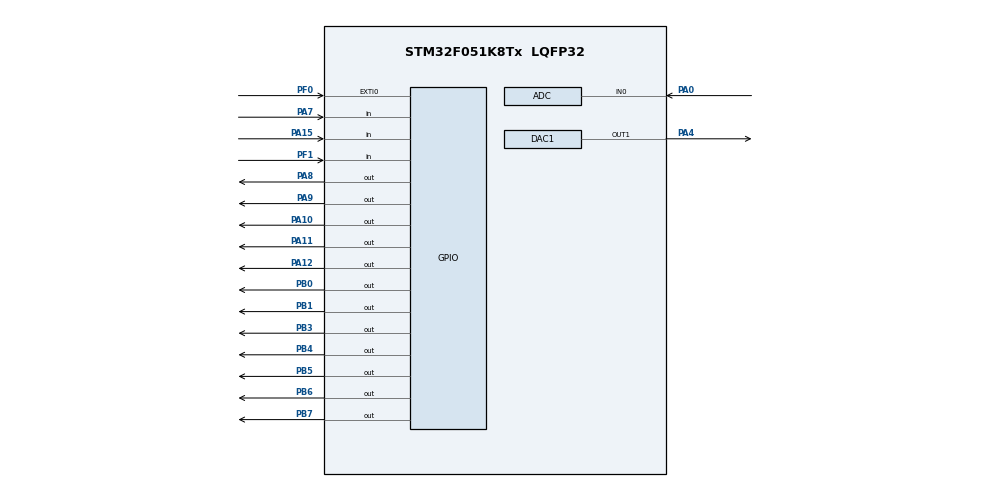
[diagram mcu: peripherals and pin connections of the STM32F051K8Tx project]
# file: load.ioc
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DAC1.DAC_OutputBuffer=DAC_OUTPUTBUFFER_DISABLE
Mcu.Family=STM32F0
Mcu.Name=STM32F051K8Tx
Mcu.Package=LQFP32
NVIC.EXTI0_1_IRQn=true\:0\:0\:false\:false\:true\:true\:true
PA0.Mode=IN0
PA0.Signal=ADC_IN0
PA10.GPIO_Speed=GPIO_SPEED_FREQ_HIGH
PA10.Signal=GPIO_Output
PA11.GPIO_Speed=GPIO_SPEED_FREQ_HIGH
PA11.PinState=GPIO_PIN_RESET
PA11.Signal=GPIO_Output
PA12.GPIO_Speed=GPIO_SPEED_FREQ_HIGH
PA12.PinState=GPIO_PIN_RESET
PA12.Signal=GPIO_Output
PA13.Mode=Serial_Wire
PA13.Signal=SYS_SWDIO
PA14.Mode=Serial_Wire
PA14.Signal=SYS_SWCLK
PA15.GPIO_PuPd=GPIO_PULLUP
PA15.Signal=GPIO_Input
PA4.Signal=COMP_DAC11_group
PA7.GPIO_PuPd=GPIO_PULLUP
PA7.Signal=GPIO_Input
PA8.GPIO_Speed=GPIO_SPEED_FREQ_HIGH
PA8.Signal=GPIO_Output
PA9.GPIO_Speed=GPIO_SPEED_FREQ_HIGH
PA9.Signal=GPIO_Output
PB0.PinState=GPIO_PIN_RESET
PB0.Signal=GPIO_Output
PB1.GPIO_Speed=GPIO_SPEED_FREQ_LOW
PB1.PinState=GPIO_PIN_RESET
PB1.Signal=GPIO_Output
PB3.GPIO_Speed=GPIO_SPEED_FREQ_HIGH
PB3.Signal=GPIO_Output
PB4.GPIO_Speed=GPIO_SPEED_FREQ_HIGH
PB4.Signal=GPIO_Output
PB5.GPIO_Speed=GPIO_SPEED_FREQ_HIGH
PB5.Signal=GPIO_Output
PB6.GPIO_Speed=GPIO_SPEED_FREQ_HIGH
PB6.Signal=GPIO_Output
PB7.GPIO_Speed=GPIO_SPEED_FREQ_HIGH
PB7.Signal=GPIO_Output
PF0-OSC_IN.GPIO_ModeDefaultEXTI=GPIO_MODE_IT_RISING
PF0-OSC_IN.Signal=GPXTI0
PF1-OSC_OUT.Signal=GPIO_Input
ProjectManager.HeapSize=0x000
ProjectManager.StackSize=0x400
ProjectManager.TargetToolchain=MDK-ARM V5
RCC.AHBCLKDivider=RCC_SYSCLK_DIV8
RCC.AHBFreq_Value=1000000
RCC.APB1Freq_Value=1000000
RCC.APB1TimFreq_Value=1000000
RCC.HCLKFreq_Value=1000000
SH.COMP_DAC11_group.0=DAC1_OUT1,DAC_OUT1
board=custom

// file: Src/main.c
/* USER CODE BEGIN Header */
/**
  ******************************************************************************
  * @file           : main.c
  * @brief          : Main program body
  ******************************************************************************
  * @attention
  *
  * <h2><center>&copy; Copyright (c) 2019 STMicroelectronics.
  * All rights reserved.</center></h2>
  *
  * This software component is licensed by ST under BSD 3-Clause license,
  * the "License"; You may not use this file except in compliance with the
  * License. You may obtain a copy of the License at:
  *                        opensource.org/licenses/BSD-3-Clause
  *
  ******************************************************************************
  */
/* USER CODE END Header */

#include "main.h"

/* USER CODE BEGIN Includes */
#include <board.h>

/* USER CODE END Includes */

ADC_HandleTypeDef hadc;

DAC_HandleTypeDef hdac1;

void SystemClock_Config(void);
static void MX_GPIO_Init(void);
static void MX_ADC_Init(void);
static void MX_DAC1_Init(void);

int main(void)
{

  /* MCU Configuration--------------------------------------------------------*/

  /* Reset of all peripherals, Initializes the Flash interface and the Systick. */
  HAL_Init();

  /* Configure the system clock */
  SystemClock_Config();

  /* Initialize all configured peripherals */
  MX_GPIO_Init();
  MX_ADC_Init();
  MX_DAC1_Init();
  /* USER CODE BEGIN 2 */

  user_init();

  /* USER CODE END 2 */

  /* Infinite loop */
  while (1)
  {

    /* USER CODE BEGIN 3 */

    user_loop();
  }
  /* USER CODE END 3 */
}

void SystemClock_Config(void)
{
  RCC_OscInitTypeDef RCC_OscInitStruct = {0};
  RCC_ClkInitTypeDef RCC_ClkInitStruct = {0};

  /** Initializes the CPU, AHB and APB busses clocks
  */
  RCC_OscInitStruct.OscillatorType = RCC_OSCILLATORTYPE_HSI|RCC_OSCILLATORTYPE_HSI14;
  RCC_OscInitStruct.HSIState = RCC_HSI_ON;
  RCC_OscInitStruct.HSI14State = RCC_HSI14_ON;
  RCC_OscInitStruct.HSICalibrationValue = RCC_HSICALIBRATION_DEFAULT;
  RCC_OscInitStruct.HSI14CalibrationValue = 16;
  RCC_OscInitStruct.PLL.PLLState = RCC_PLL_NONE;
  if (HAL_RCC_OscConfig(&RCC_OscInitStruct) != HAL_OK)
  {
    Error_Handler();
  }
  /** Initializes the CPU, AHB and APB busses clocks
  */
  RCC_ClkInitStruct.ClockType = RCC_CLOCKTYPE_HCLK|RCC_CLOCKTYPE_SYSCLK
                              |RCC_CLOCKTYPE_PCLK1;
  RCC_ClkInitStruct.SYSCLKSource = RCC_SYSCLKSOURCE_HSI;
  RCC_ClkInitStruct.AHBCLKDivider = RCC_SYSCLK_DIV8;
  RCC_ClkInitStruct.APB1CLKDivider = RCC_HCLK_DIV1;

  if (HAL_RCC_ClockConfig(&RCC_ClkInitStruct, FLASH_LATENCY_0) != HAL_OK)
  {
    Error_Handler();
  }
}

static void MX_ADC_Init(void)
{

  ADC_ChannelConfTypeDef sConfig = {0};

  /** Configure the global features of the ADC (Clock, Resolution, Data Alignment and number of conversion)
  */
  hadc.Instance = ADC1;
  hadc.Init.ClockPrescaler = ADC_CLOCK_ASYNC_DIV1;
  hadc.Init.Resolution = ADC_RESOLUTION_12B;
  hadc.Init.DataAlign = ADC_DATAALIGN_RIGHT;
  hadc.Init.ScanConvMode = ADC_SCAN_DIRECTION_FORWARD;
  hadc.Init.EOCSelection = ADC_EOC_SINGLE_CONV;
  hadc.Init.LowPowerAutoWait = DISABLE;
  hadc.Init.LowPowerAutoPowerOff = DISABLE;
  hadc.Init.ContinuousConvMode = DISABLE;
  hadc.Init.DiscontinuousConvMode = DISABLE;
  hadc.Init.ExternalTrigConv = ADC_SOFTWARE_START;
  hadc.Init.ExternalTrigConvEdge = ADC_EXTERNALTRIGCONVEDGE_NONE;
  hadc.Init.DMAContinuousRequests = DISABLE;
  hadc.Init.Overrun = ADC_OVR_DATA_PRESERVED;
  if (HAL_ADC_Init(&hadc) != HAL_OK)
  {
    Error_Handler();
  }
  /** Configure for the selected ADC regular channel to be converted.
  */
  sConfig.Channel = ADC_CHANNEL_0;
  sConfig.Rank = ADC_RANK_CHANNEL_NUMBER;
  sConfig.SamplingTime = ADC_SAMPLETIME_1CYCLE_5;
  if (HAL_ADC_ConfigChannel(&hadc, &sConfig) != HAL_OK)
  {
    Error_Handler();
  }

}

static void MX_DAC1_Init(void)
{

  DAC_ChannelConfTypeDef sConfig = {0};

  /** DAC Initialization
  */
  hdac1.Instance = DAC;
  if (HAL_DAC_Init(&hdac1) != HAL_OK)
  {
    Error_Handler();
  }
  /** DAC channel OUT1 config
  */
  sConfig.DAC_Trigger = DAC_TRIGGER_NONE;
  sConfig.DAC_OutputBuffer = DAC_OUTPUTBUFFER_DISABLE;
  if (HAL_DAC_ConfigChannel(&hdac1, &sConfig, DAC_CHANNEL_1) != HAL_OK)
  {
    Error_Handler();
  }

}

static void MX_GPIO_Init(void)
{
  GPIO_InitTypeDef GPIO_InitStruct = {0};

  /* GPIO Ports Clock Enable */
  __HAL_RCC_GPIOF_CLK_ENABLE();
  __HAL_RCC_GPIOA_CLK_ENABLE();
  __HAL_RCC_GPIOB_CLK_ENABLE();

  /*Configure GPIO pin Output Level */
  HAL_GPIO_WritePin(GPIOB, GPIO_PIN_0|GPIO_PIN_1|GPIO_PIN_3|GPIO_PIN_4
                          |GPIO_PIN_5|GPIO_PIN_6|GPIO_PIN_7, GPIO_PIN_RESET);

  /*Configure GPIO pin Output Level */
  HAL_GPIO_WritePin(GPIOA, GPIO_PIN_8|GPIO_PIN_9|GPIO_PIN_10|GPIO_PIN_11
                          |GPIO_PIN_12, GPIO_PIN_RESET);

  /*Configure GPIO pin : PF0 */
  GPIO_InitStruct.Pin = GPIO_PIN_0;
  GPIO_InitStruct.Mode = GPIO_MODE_IT_RISING;
  GPIO_InitStruct.Pull = GPIO_NOPULL;
  HAL_GPIO_Init(GPIOF, &GPIO_InitStruct);

  /*Configure GPIO pin : PF1 */
  GPIO_InitStruct.Pin = GPIO_PIN_1;
  GPIO_InitStruct.Mode = GPIO_MODE_INPUT;
  GPIO_InitStruct.Pull = GPIO_NOPULL;
  HAL_GPIO_Init(GPIOF, &GPIO_InitStruct);

  /*Configure GPIO pins : PA7 PA15 */
  GPIO_InitStruct.Pin = GPIO_PIN_7|GPIO_PIN_15;
  GPIO_InitStruct.Mode = GPIO_MODE_INPUT;
  GPIO_InitStruct.Pull = GPIO_PULLUP;
  HAL_GPIO_Init(GPIOA, &GPIO_InitStruct);

  /*Configure GPIO pins : PB0 PB1 */
  GPIO_InitStruct.Pin = GPIO_PIN_0|GPIO_PIN_1;
  GPIO_InitStruct.Mode = GPIO_MODE_OUTPUT_PP;
  GPIO_InitStruct.Pull = GPIO_NOPULL;
  GPIO_InitStruct.Speed = GPIO_SPEED_FREQ_LOW;
  HAL_GPIO_Init(GPIOB, &GPIO_InitStruct);

  /*Configure GPIO pins : PA8 PA9 PA10 PA11
                           PA12 */
  GPIO_InitStruct.Pin = GPIO_PIN_8|GPIO_PIN_9|GPIO_PIN_10|GPIO_PIN_11
                          |GPIO_PIN_12;
  GPIO_InitStruct.Mode = GPIO_MODE_OUTPUT_PP;
  GPIO_InitStruct.Pull = GPIO_NOPULL;
  GPIO_InitStruct.Speed = GPIO_SPEED_FREQ_HIGH;
  HAL_GPIO_Init(GPIOA, &GPIO_InitStruct);

  /*Configure GPIO pins : PB3 PB4 PB5 PB6
                           PB7 */
  GPIO_InitStruct.Pin = GPIO_PIN_3|GPIO_PIN_4|GPIO_PIN_5|GPIO_PIN_6
                          |GPIO_PIN_7;
  GPIO_InitStruct.Mode = GPIO_MODE_OUTPUT_PP;
  GPIO_InitStruct.Pull = GPIO_NOPULL;
  GPIO_InitStruct.Speed = GPIO_SPEED_FREQ_HIGH;
  HAL_GPIO_Init(GPIOB, &GPIO_InitStruct);

  /* EXTI interrupt init*/
  HAL_NVIC_SetPriority(EXTI0_1_IRQn, 0, 0);
  HAL_NVIC_EnableIRQ(EXTI0_1_IRQn);

}

void Error_Handler(void)
{
}

/************************ (C) COPYRIGHT STMicroelectronics *****END OF FILE****/
